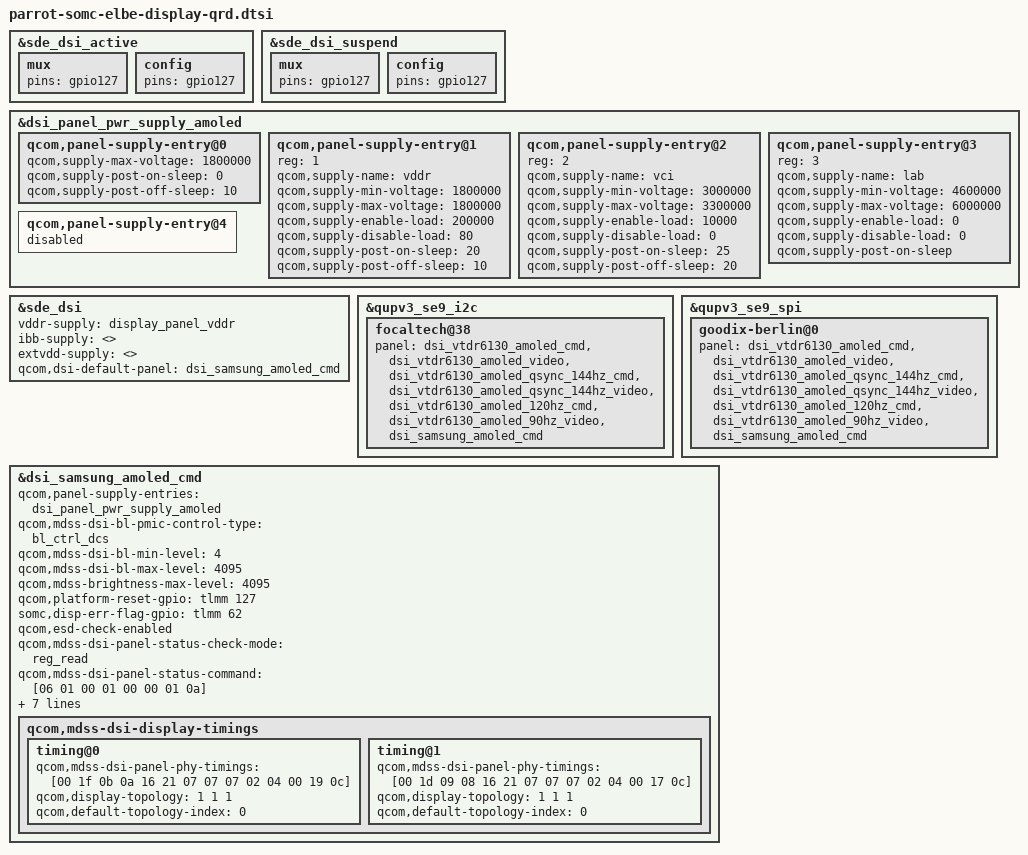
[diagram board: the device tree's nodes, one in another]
&sde_dsi_active  {
	mux {
		pins = "gpio127";
	};
	config {
		pins = "gpio127";
	};
};

&sde_dsi_suspend {
	mux {
		pins = "gpio127";
	};
	config {
		pins = "gpio127";
	};
};

&dsi_panel_pwr_supply_amoled {
	qcom,panel-supply-entry@0 {
		qcom,supply-max-voltage = <1800000>;
		qcom,supply-post-on-sleep = <0>;
		qcom,supply-post-off-sleep = <10>;
	};

	qcom,panel-supply-entry@1 {
		reg = <1>;
		qcom,supply-name = "vddr";
		qcom,supply-min-voltage = <1800000>;
		qcom,supply-max-voltage = <1800000>;
		qcom,supply-enable-load = <200000>;
		qcom,supply-disable-load = <80>;
		qcom,supply-post-on-sleep = <20>;
		qcom,supply-post-off-sleep = <10>;
	};

	qcom,panel-supply-entry@2 {
		reg = <2>;
		qcom,supply-name = "vci";
		qcom,supply-min-voltage = <3000000>;
		qcom,supply-max-voltage = <3300000>;
		qcom,supply-enable-load = <10000>;
		qcom,supply-disable-load = <0>;
		qcom,supply-post-on-sleep = <25>;
		qcom,supply-post-off-sleep = <20>;
	};

	qcom,panel-supply-entry@3 {
		reg = <3>;
		qcom,supply-name = "lab";
		qcom,supply-min-voltage = <4600000>;
		qcom,supply-max-voltage = <6000000>;
		qcom,supply-enable-load = <0>;
		qcom,supply-disable-load = <0>;
		qcom,supply-post-on-sleep;
	};

	qcom,panel-supply-entry@4 {
		status = "disabled";
	};
};

&sde_dsi {
	vddr-supply = <&display_panel_vddr>;
	ibb-supply = <>;
	extvdd-supply = <>;
	qcom,dsi-default-panel = <&dsi_samsung_amoled_cmd>;
};

&qupv3_se9_i2c {
	focaltech@38 {
		panel = <&dsi_vtdr6130_amoled_cmd
			&dsi_vtdr6130_amoled_video
			&dsi_vtdr6130_amoled_qsync_144hz_cmd
			&dsi_vtdr6130_amoled_qsync_144hz_video
			&dsi_vtdr6130_amoled_120hz_cmd
			&dsi_vtdr6130_amoled_90hz_video
			&dsi_samsung_amoled_cmd>;
	};
};

&qupv3_se9_spi {
	goodix-berlin@0 {
		panel = <&dsi_vtdr6130_amoled_cmd
			&dsi_vtdr6130_amoled_video
			&dsi_vtdr6130_amoled_qsync_144hz_cmd
			&dsi_vtdr6130_amoled_qsync_144hz_video
			&dsi_vtdr6130_amoled_120hz_cmd
			&dsi_vtdr6130_amoled_90hz_video
			&dsi_samsung_amoled_cmd>;
	};
};

&dsi_samsung_amoled_cmd {
	qcom,panel-supply-entries = <&dsi_panel_pwr_supply_amoled>;
	qcom,mdss-dsi-bl-pmic-control-type = "bl_ctrl_dcs";
	qcom,mdss-dsi-bl-min-level = <4>;
	qcom,mdss-dsi-bl-max-level = <4095>;
	qcom,mdss-brightness-max-level = <4095>;
	qcom,platform-reset-gpio = <&tlmm 127 0>;
	somc,disp-err-flag-gpio = <&tlmm 62 0>;
	qcom,esd-check-enabled;
	qcom,mdss-dsi-panel-status-check-mode = "reg_read";
	qcom,mdss-dsi-panel-status-command = [06 01 00 01 00 00 01 0a];
	qcom,mdss-dsi-panel-status-command-state = "dsi_lp_mode";
	qcom,mdss-dsi-panel-status-value = <0x9C>;
	qcom,mdss-dsi-panel-status-read-length = <1>;
	qcom,ulps-enabled;
	qcom,dsi-select-clocks = "pll_byte_clk0", "pll_dsi_clk0";
	qcom,mdss-dsi-display-timings {
		timing@0 {
			qcom,mdss-dsi-panel-phy-timings = [00 1f 0b 0a 16 21 07
				07 07 02 04 00 19 0c];
			qcom,display-topology = <1 1 1>;
			qcom,default-topology-index = <0>;
		};
		timing@1 {
			qcom,mdss-dsi-panel-phy-timings = [00 1d 09 08 16 21 07
				07 07 02 04 00 17 0c];
			qcom,display-topology = <1 1 1>;
			qcom,default-topology-index = <0>;
		};
	};
};
